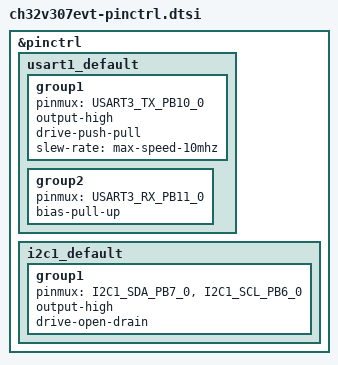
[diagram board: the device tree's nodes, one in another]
/*
 * Copyright (c) 2025 Thomas Boje
 * SPDX-License-Identifier: Apache-2.0
 */

#include <zephyr/dt-bindings/pinctrl/ch32v20x_30x-pinctrl.h>

&pinctrl {
	usart1_default: usart1_default {
		group1 {
			pinmux = <USART3_TX_PB10_0>;
			output-high;
			drive-push-pull;
			slew-rate = "max-speed-10mhz";
		};
		group2 {
			pinmux = <USART3_RX_PB11_0>;
			bias-pull-up;
		};
	};

	i2c1_default: i2c1_default {
		group1 {
			pinmux = <I2C1_SDA_PB7_0>, <I2C1_SCL_PB6_0>;
			output-high;
			drive-open-drain;
		};
	};
};
